# NAVSS0_NAV_DDR_HI_VIRTID_CFG_MMRS register map
Vendor: Texas Instruments
Peripheral module from a debugger description file (folder am65x).
Registers are 32-bit, read-only, reset values left out (the file's numbers can be read two ways) unless marked. A register's access mark holds for its fields unless they carry their own. Offsets are as the file gives them; lines under a group give offsets from that group; [hi:lo] are bit positions; {n}, {i} and the like mark numbered series; 'fields as' and 'values as' point back to an identical list; <NAME> marks a mode.

## NAVSS0_NAV_DDR_HI_VIRTID_CFG_MMRS
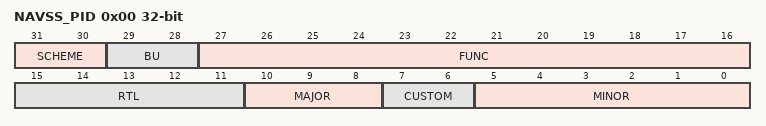
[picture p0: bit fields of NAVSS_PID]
0x00 NAVSS_PID — The Revision Register contains the major and minor revisions for the module.
  [31:30] SCHEME
  [29:28] BU
  [27:16] FUNC — Module ID
  [15:11] RTL — RTL revision. Will vary depending on release.
  [10:8] MAJOR — Major revision
  [7:6] CUSTOM
  [5:0] MINOR — Minor revision
0x00 NAVSS_WINDOW_Y rw — The VirtID for window a. Offset = 10h + (y * 4h); where y = 0h to Fh
  [11:0] VIRTID — VirtID for window a.
